# CH592SFR register map
Vendor: WCH Ltd.; Series: CH59x; File version: 1.0
CPU: other r0p0, little endian, no MPU, no FPU, 2 interrupt priority bits
Registers are 8-bit, read-write, reset 0x0 unless marked. A register's access mark holds for its fields unless they carry their own. Offsets are from the block's base; [hi:lo] are bit positions; {n}, {i} and the like mark numbered series.

## TMR3 — Timer3 register
Base 0x40002C00
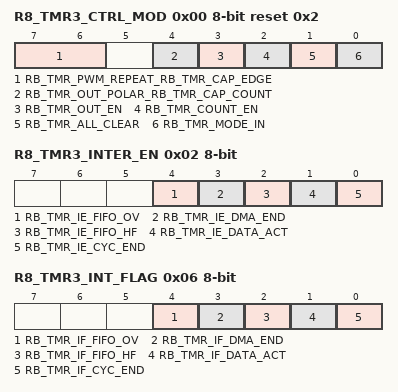
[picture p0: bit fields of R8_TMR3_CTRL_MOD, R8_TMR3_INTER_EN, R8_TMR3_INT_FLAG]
0x00 R8_TMR3_CTRL_MOD reset 0x2 — RW, TMR3 mode control
  [7:6] RB_TMR_PWM_REPEAT_RB_TMR_CAP_EDGE — RW, timer PWM repeat mode: 00=1, 01=4, 10=8, 11-16;RW, timer capture edge mode: 00=disable, 01=edge change, 10=fall to fall, 11-rise to rise
  [4] RB_TMR_OUT_POLAR_RB_TMR_CAP_COUNT — RW, timer PWM output polarity: 0=default low and high action, 1=default high and low action;RW, count sub-mode if RB_TMR_MODE_IN=1: 0=capture, 1=count
  [3] RB_TMR_OUT_EN — RW, timer output enable
  [2] RB_TMR_COUNT_EN — RW, timer count enable
  [1] RB_TMR_ALL_CLEAR — RW, force clear timer FIFO and count
  [0] RB_TMR_MODE_IN — RW, timer in mode: 0=timer/PWM, 1=capture/count
0x02 R8_TMR3_INTER_EN — RW, TMR3 interrupt enable
  [4] RB_TMR_IE_FIFO_OV — RW, enable interrupt for timer FIFO overflow
  [3] RB_TMR_IE_DMA_END — RW, enable interrupt for timer1/2 DMA completion
  [2] RB_TMR_IE_FIFO_HF — RW, enable interrupt for timer FIFO half (capture fifo more than 4 or PWM fifo less than 3)
  [1] RB_TMR_IE_DATA_ACT — RW, enable interrupt for timer capture input action or PWM trigger
  [0] RB_TMR_IE_CYC_END — RW, enable interrupt for timer capture count timeout or PWM cycle end
0x06 R8_TMR3_INT_FLAG — RW1, TMR3 interrupt flag
  [4] RB_TMR_IF_FIFO_OV — RW1, interrupt flag for timer FIFO overflow
  [3] RB_TMR_IF_DMA_END — RW1, interrupt flag for timer1/2 DMA completion
  [2] RB_TMR_IF_FIFO_HF — RW1, interrupt flag for timer FIFO half (capture fifo more than 4 or PWM fifo less than 3)
  [1] RB_TMR_IF_DATA_ACT — RW1, interrupt flag for timer capture input action or PWM trigger
  [0] RB_TMR_IF_CYC_END — RW1, interrupt flag for timer capture count timeout or PWM cycle end
0x07 R8_TMR3_FIFO_COUNT ro — RO, TMR3 FIFO count status
  [3:0] R8_TMR3_FIFO_COUNT
0x08 R32_TMR3_COUNT 32-bit ro — RO, TMR3 current count
  [25:0] R32_TMR3_COUNT
0x0C R32_TMR3_CNT_END 32-bit — RW, TMR3 end count value, only low 26 bit
0x10 R32_TMR3_FIFO 32-bit — RO/WO, TMR3 FIFO register, only low 26 bit

## SPI0
Base 0x40004000
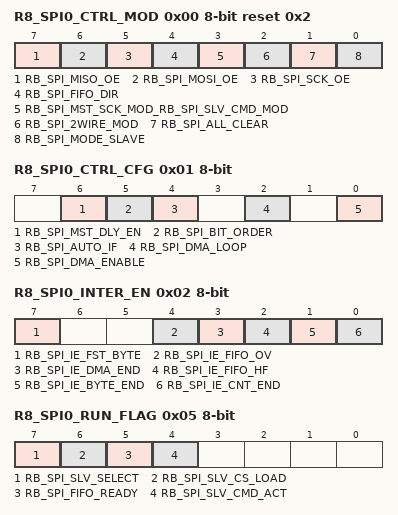
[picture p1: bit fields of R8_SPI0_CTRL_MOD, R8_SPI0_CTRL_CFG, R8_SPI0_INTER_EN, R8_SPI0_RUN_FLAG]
0x00 R8_SPI0_CTRL_MOD reset 0x2 — RW, SPI0 mode control
  [7] RB_SPI_MISO_OE — RW, SPI MISO output enable
  [6] RB_SPI_MOSI_OE — RW, SPI MOSI output enable
  [5] RB_SPI_SCK_OE — RW, SPI SCK output enable
  [4] RB_SPI_FIFO_DIR — RW, SPI FIFO direction: 0=out(write @master mode), 1=in(read @master mode)
  [3] RB_SPI_MST_SCK_MOD_RB_SPI_SLV_CMD_MOD — RW, SPI master clock mode: 0=mode 0, 1=mode 3;RW, SPI0 slave command mode: 0=byte stream, 1=first byte command
  [2] RB_SPI_2WIRE_MOD — RW, SPI0 enable 2 wire mode for slave: 0=3wire(SCK0,MOSI,MISO), 1=2wire(SCK0,MISO=MXSX)
  [1] RB_SPI_ALL_CLEAR — RW, force clear SPI FIFO and count
  [0] RB_SPI_MODE_SLAVE — RW, SPI0 slave mode: 0=master or host, 1=slave or device
0x01 R8_SPI0_CTRL_CFG — RW, SPI0 configuration control
  [6] RB_SPI_MST_DLY_EN — RW, SPI master input delay enable
  [5] RB_SPI_BIT_ORDER — RW, SPI bit data order: 0=MSB first, 1=LSB first
  [4] RB_SPI_AUTO_IF — RW, enable buffer/FIFO accessing to auto clear RB_SPI_IF_BYTE_END interrupt flag
  [2] RB_SPI_DMA_LOOP — RW, SPI0 DMA address loop enable
  [0] RB_SPI_DMA_ENABLE — RW, SPI0 DMA enable
0x02 R8_SPI0_INTER_EN — RW, SPI0 interrupt enable
  [7] RB_SPI_IE_FST_BYTE — RW, enable interrupt for SPI0 slave mode first byte received
  [4] RB_SPI_IE_FIFO_OV — RW, enable interrupt for SPI0 FIFO overflow
  [3] RB_SPI_IE_DMA_END — RW, enable interrupt for SPI0 DMA completion
  [2] RB_SPI_IE_FIFO_HF — RW, enable interrupt for SPI FIFO half
  [1] RB_SPI_IE_BYTE_END — RW, enable interrupt for SPI byte exchanged
  [0] RB_SPI_IE_CNT_END — RW, enable interrupt for SPI total byte count end
0x03 R8_SPI0_CLOCK_DIV_R8_SPI0_SLAVE_PRE reset 0x10 — RW, SPI0 master clock divisor;RW, SPI0 slave preset value
0x04 R8_SPI0_BUFFER — RW, SPI0 data buffer
0x05 R8_SPI0_RUN_FLAG ro — RO, SPI0 work flag
  [7] RB_SPI_SLV_SELECT — RO, SPI0 slave selection status
  [6] RB_SPI_SLV_CS_LOAD — RO, SPI0 slave chip-select loading status
  [5] RB_SPI_FIFO_READY — RO, SPI FIFO ready status
  [4] RB_SPI_SLV_CMD_ACT — RO, SPI0 slave first byte or command flag
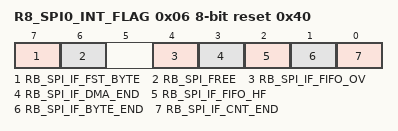
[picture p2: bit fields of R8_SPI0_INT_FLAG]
0x06 R8_SPI0_INT_FLAG reset 0x40 — RW1, SPI0 interrupt flag
  [7] RB_SPI_IF_FST_BYTE — RW1, interrupt flag for SPI0 slave mode first byte received
  [6] RB_SPI_FREE — RO, current SPI free status
  [4] RB_SPI_IF_FIFO_OV — RW1, interrupt flag for SPI0 FIFO overflow
  [3] RB_SPI_IF_DMA_END — RW1, interrupt flag for SPI0 DMA completion
  [2] RB_SPI_IF_FIFO_HF — RW1, interrupt flag for SPI FIFO half
  [1] RB_SPI_IF_BYTE_END — RW1, interrupt flag for SPI byte exchanged
  [0] RB_SPI_IF_CNT_END — RW1, interrupt flag for SPI total byte count end
0x07 R8_SPI0_FIFO_COUNT — RW, SPI0 FIFO count status
  [3:0] R8_SPI0_FIFO_COUNT
0x0C R16_SPI0_TOTAL_CNT 16-bit — RW, SPI0 total byte count, only low 12 bit
0x10 R8_SPI0_FIFO — RO/WO, SPI0 FIFO register
0x13 R8_SPI0_FIFO_COUNT1 ro — RO, SPI0 FIFO count status
0x14 R16_SPI0_DMA_NOW 16-bit — RW, SPI0 DMA current address
0x18 R16_SPI0_DMA_BEG 16-bit — RW, SPI0 DMA begin address
0x1C R16_SPI0_DMA_END 16-bit — RW, SPI0 DMA end address

## PWMx
Base 0x40005000
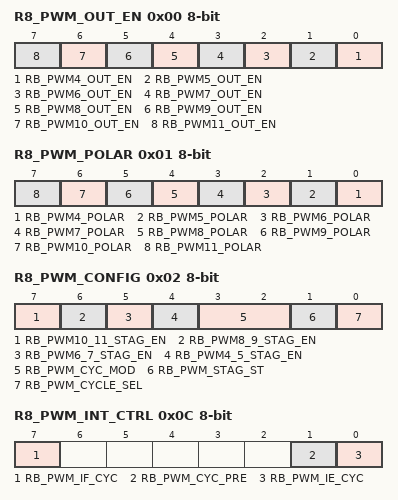
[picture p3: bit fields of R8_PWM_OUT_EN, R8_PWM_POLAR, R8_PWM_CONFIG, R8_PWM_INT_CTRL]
0x00 R8_PWM_OUT_EN — RW, PWM output enable control
  [n-4] RB_PWM{n}_OUT_EN (n=4..11) — RW, PWM{n} output enable
0x01 R8_PWM_POLAR — RW, PWM output polarity control
  [n-4] RB_PWM{n}_POLAR (n=4..11) — RW, PWM{n} output polarity: 0=default low and high action, 1=default high and low action
0x02 R8_PWM_CONFIG — RW, PWM configuration
  [7] RB_PWM10_11_STAG_EN — RW, PWM10/11 stagger output enable: 0=independent output, 1=stagger output
  [6] RB_PWM8_9_STAG_EN — RW, PWM8/9 stagger output enable: 0=independent output, 1=stagger output
  [5] RB_PWM6_7_STAG_EN — RW, PWM6/7 stagger output enable: 0=independent output, 1=stagger output
  [4] RB_PWM4_5_STAG_EN — RW, PWM4/5 stagger output enable: 0=independent output, 1=stagger output
  [3:2] RB_PWM_CYC_MOD — RW, PWM data width mode: 00=8 bits data, 01=7 bits data, 10=6 bits data, 11=5 bits data
  [1] RB_PWM_STAG_ST ro — RO, PWM stagger cycle status
  [0] RB_PWM_CYCLE_SEL — RW, PWM cycle selection: 0=256;128;64;32 clocks, 1=255;127;63;31 clocks
0x03 R8_PWM_CLOCK_DIV — RW, PWM clock divisor
{0x0+i} R8_PWM{i}_DATA (i=4..11) — RW, PWM{i} data holding
0x0C R8_PWM_INT_CTRL — RW, PWM interrupt control
  [7] RB_PWM_IF_CYC — RW1, interrupt flag for PWM cycle end
  [1] RB_PWM_CYC_PRE — RW, select PWM cycle interrupt point
  [0] RB_PWM_IE_CYC — RW, enable interrupt for PWM cycle end
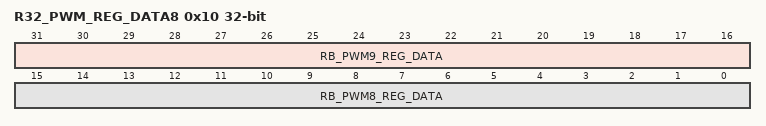
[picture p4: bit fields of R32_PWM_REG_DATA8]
0x10 R32_PWM_REG_DATA8 32-bit — RW, PWM8/9 data register
  [31:16] RB_PWM9_REG_DATA — RW, 16 bit data of PWM9 channel
  [15:0] RB_PWM8_REG_DATA — RW, 16 bit data of PWM8 channel
0x14 R32_PWM_REG_CYCLE 32-bit — RW, PWM cycle end register
  [15:0] RB_PWM_CYC_VALUE — RW, PWM End Cycles

## LCD
Base 0x40006000
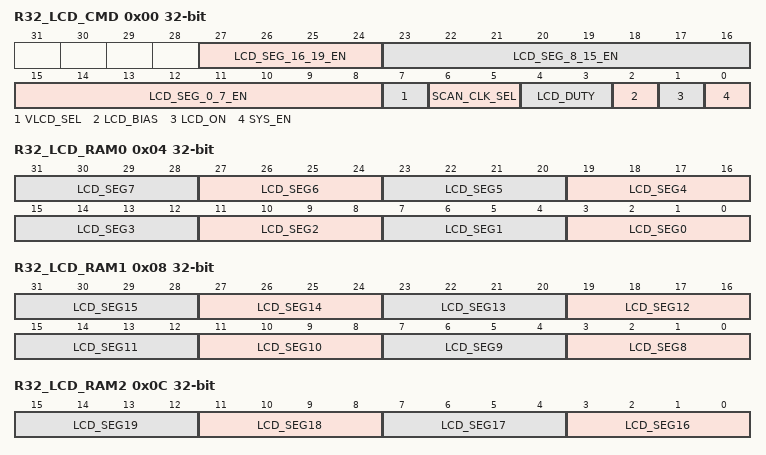
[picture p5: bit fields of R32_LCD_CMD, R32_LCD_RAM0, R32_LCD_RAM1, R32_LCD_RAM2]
0x00 R32_LCD_CMD 32-bit — RW, LCD Command Register
  [27:24] LCD_SEG_16_19_EN — RW, Enabling SEG16-SEG19 segments
  [23:16] LCD_SEG_8_15_EN — RW, Enabling SEG8-SEG15 segments
  [15:8] LCD_SEG_0_7_EN — RW, Enabling SEG0-SEG7 segments
  [7] VLCD_SEL — RW, LCD driver voltage selection
  [6:5] SCAN_CLK_SEL — RW, Scan clock selection
  [4:3] LCD_DUTY — RW, LCD duty cycle selection
  [2] LCD_BIAS — RW, PWM6 Bias ratio selection enable
  [1] LCD_ON — RW, LCD switch
  [0] SYS_EN — RW, System Enable
0x04 R32_LCD_RAM0 32-bit — RW, LCD RAM0 register
  [4n+3:4n] LCD_SEG{n} (n=0..7) — RW, SEG{n} segment data
0x08 R32_LCD_RAM1 32-bit — RW, LCD RAM1 register
  [4n-29:4n-32] LCD_SEG{n} (n=8..15) — RW, SEG{n} segment data
0x0C R32_LCD_RAM2 32-bit — RW, LCD RAM2 register
  [4n-61:4n-64] LCD_SEG{n} (n=16..19) — RW, SEG{n} segment data

## Systick
Base 0xE000F000
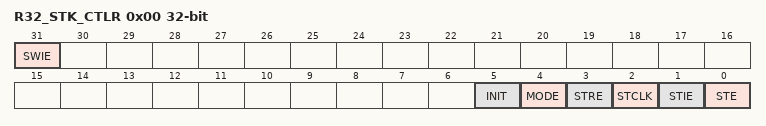
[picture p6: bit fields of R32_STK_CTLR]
0x00 R32_STK_CTLR 32-bit — Systick counter control register
  [31] SWIE — RW0,System soft interrupt enable
  [5] INIT — Initial counter value updated
  [4] MODE — counter mode
  [3] STRE — System counter reload control
  [2] STCLK — System counter clock Source selection
  [1] STIE — Systick counter interrupt enable
  [0] STE — Systick counter enable
0x04 R32_STK_SR 32-bit — Systick count status register
  [0] CNTIF — RW,CNTIF
0x08 R32_STK_CNTL 32-bit — Systick counter low register
  [31:0] CNTL — RW,CNTL
0x0C R32_STK_CNTH 32-bit — Systick counter high register
  [31:0] CNTH — RW,CNTH
0x10 R32_STK_CMPLR 32-bit — Systick compare low register
  [31:0] CMPL — RW,CMPL
0x14 R32_STK_CMPHR 32-bit — Systick compare high register
  [31:0] CMPH — RW,CMPH
